# PIC32CX0525SG12084 register map
Vendor: Microchip Technology; Series: 0525SG12; File version: 0
CPU: CM4 r1p0, little endian, no MPU, no FPU, 3 interrupt priority bits, 172 interrupts
Registers are 32-bit, read-write, reset 0x0 unless marked. A register's access mark holds for its fields unless they carry their own. Offsets are from the block's base; [hi:lo] are bit positions; 'fields as' and 'values as' point back to an identical list.

## DMA_MAIN — DMA Main Registers
Base 0x40002400
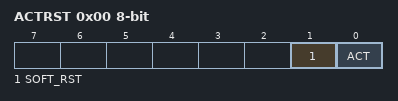
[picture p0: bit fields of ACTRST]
0x00 ACTRST 8-bit — Soft reset the entire module. Enable the blocks operation.
  [1] SOFT_RST — Soft reset the entire module. This bit is self-clearing.
  [0] ACT — Enable the blocks operation. (R/WS). 1=Enable block. Each individual channel must be enabled separately. 0=Disable all channels.
0x04 DATA_PKT ro — Debug register that has the data that is stored in the Data Packet. This data is read data from the currently active transfer source.

## GCR — The Logical Device Configuration registers support motherboard designs in which the resources required by their components are known and assigned by the BIOS at POST.
Base 0x400FFF00
0x07 LDN 8-bit — A write to this register selects the current logical device. This allows access to the control and configuration registers for each logical device. Note: The Activate command operates only on the selected logical device.
0x1C DEV_REV 8-bit ro — A read-only register which provides device revision information.
0x1D DEV_SUBID 8-bit ro reset 0x22 — A read-only register which provides device sub ID information.
0x1E DEV_ID 16-bit ro reset 0x20 — A read-only register which provides device identification.
0x20 LEG_DEV_ID 8-bit ro reset 0xFE — A read-only register which provides legacy device identification.
0x21 LEG_DEV_REV 8-bit ro reset 0xA0 — A read-only register which provides legacy device revision information.

## PORT92 — The registers listed in the Configuration Register Summary table are for a single instance of the Legacy Port92/GATEA20 logic.
Base 0x400F2000
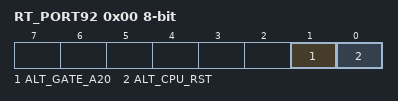
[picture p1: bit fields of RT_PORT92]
0x00 RT_PORT92 8-bit — PORT92 Register: The registers listed in the Runtime Register Summary table are for a single instance of the Legacy Port92/GATEA20 logic.
  [1] ALT_GATE_A20 — This bit provides an alternate means for system control of the GATEA20 pin. ALT_A20 low drives GATEA20 low, if A20 from the keyboard controller is also low. When Port 92 is enabled, writing a 1 to this bit forces ALT_A20 high. ALT_A20 high drives GATEA20 high regardless of the state of A20 from the keyboard controller. 0=ALT_A20 is driven low; 1=ALT_A20 is driven high
  [0] ALT_CPU_RST — This bit provides an alternate means to generate a CPU_RESET pulse.
0x100 GATEA20 8-bit — GATEA20 Control Register
  [0] GATEA20 — 0=The GATEA20 output is driven low, 1=The GATEA20 output is driven high.
0x108 SETGA20L 8-bit wo — SETGA20L Register. A write to this register sets GATEA20 in the GATEA20 Control Register.
0x10C RSTGA20L 8-bit — RSTGA20L Register. A write to this register sets GATEA20 in the GATEA20 Control Register.
0x330 EN 8-bit — PORT92 Enable Register
  [0] EN — When this bit is '1', the Port92h Register is enabled. When this bit is '0', the Port92h Register is disabled, and Host writes to Host address 92h are ignored.

## PM1 — These features comply with the ACPI Specification through a combination of hardware and EC software
Base 0x400F1C00
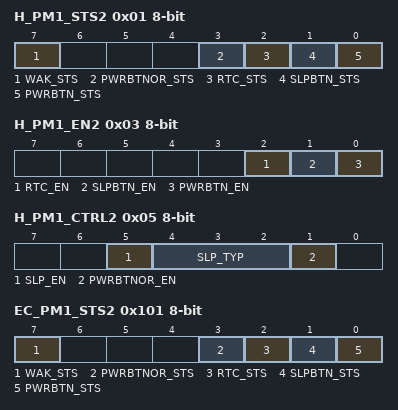
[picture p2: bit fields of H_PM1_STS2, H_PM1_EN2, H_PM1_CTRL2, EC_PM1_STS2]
0x01 H_PM1_STS2 8-bit — PM1 Status 2
  [7] WAK_STS — This bit can be set or cleared by the EC. The Host writing a one to this bit can also clear this bit. (R/WC)
  [3] PWRBTNOR_STS — This bit can be set or cleared by the EC to simulate a Power button override event status if the power is controlled by the EC. The Host writing a one to this bit can also clear this bit. The EC must generate the associated hardware event under software control.(R/WC)
  [2] RTC_STS — This bit can be set or cleared by the EC to simulate a RTC status. The Host writing a one to this bit can also clear this bit. The EC must generate the associated SCI interrupt under software control. (R/WC)
  [1] SLPBTN_STS — This bit can be set or cleared by the EC to simulate a Sleep button status if the sleep state is controlled by the EC. The Host writing a one to this bit can also clear this bit. The EC must generate the associated SCI interrupt under software control.(R/WC)
  [0] PWRBTN_STS — This bit can be set or cleared by the EC to simulate a Power button status if the power is controlled by the EC. The Host writing a one to this bit can also clear this bit. The EC must generate the associated SCI interrupt under software control. (R/WC)
0x03 H_PM1_EN2 8-bit — PM1 Enable 2
  [2] RTC_EN — This bit can be read or written by the Host. It can be read by the EC.
  [1] SLPBTN_EN — This bit can be read or written by the Host. It can be read by the EC.
  [0] PWRBTN_EN — This bit can be read or written by the Host. It can be read by the EC.
0x05 H_PM1_CTRL2 8-bit — PM1 Control 2
  [5] SLP_EN
  [4:2] SLP_TYP — These bits can be set or cleared by the Host, read by the EC.
  [1] PWRBTNOR_EN — This bit can be set or cleared by the Host, read by the EC.
0x101 EC_PM1_STS2 8-bit — PM1 Status 2
  fields as H_PM1_STS2
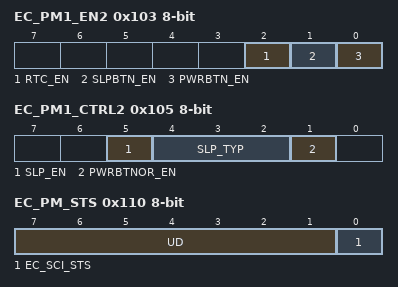
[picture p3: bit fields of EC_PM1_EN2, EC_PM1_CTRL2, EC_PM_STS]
0x103 EC_PM1_EN2 8-bit — PM1 Enable 2
  fields as H_PM1_EN2
0x105 EC_PM1_CTRL2 8-bit — PM1 Control 2
  fields as H_PM1_CTRL2
0x110 EC_PM_STS 8-bit — PM1 EC PM Status
  [7:1] UD — User Defined
  [0] EC_SCI_STS — If the EC_SCI_STS bit is '1', an interrupt is generated on the EC_SCI# pin.

## Notices in the file
Copyright (c) 2023 Microchip Technology Inc.
SPDX-License-Identifier: Apache-2.0
Licensed under the Apache License, Version 2.0 (the "License");
you may not use this file except in compliance with the License.
You may obtain a copy of the License at
http://www.apache.org/licenses/LICENSE-2.0
Unless required by applicable law or agreed to in writing, software
distributed under the License is distributed on an "AS IS" BASIS,
WITHOUT WARRANTIES OR CONDITIONS OF ANY KIND, either express or implied.
See the License for the specific language governing permissions and
limitations under the License.
